AUTOSAR XML (schema 00051)
package /Components
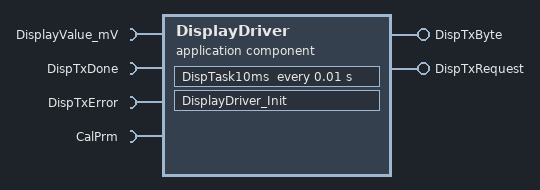
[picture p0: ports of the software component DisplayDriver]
  application sw component type DisplayDriver
    require port DisplayValue_mV: nonqueued-receiver-com-spec{data-element=DisplayValue_mV, init-value=0}, required-interface=DisplayValue_mV
    require port DispTxDone: nonqueued-receiver-com-spec{data-element=DispTxDone, init-value=0}, required-interface=DispTxDone
    require port DispTxError: nonqueued-receiver-com-spec{data-element=DispTxError, init-value=0}, required-interface=DispTxError
    provide port DispTxByte: nonqueued-sender-com-spec{data-element=DispTxByte, init-value=0}, provided-interface=DispTxByte
    provide port DispTxRequest: nonqueued-sender-com-spec{data-element=DispTxRequest, init-value=0}, provided-interface=DispTxRequest
    require port CalPrm: required-interface=CalPrm
      required-com-specs:
        init-value=CalPrm_DisplayRefresh_cycles:100, parameter=DisplayRefresh_cycles
        init-value=CalPrm_DisplayRetry_cycles:50, parameter=DisplayRetry_cycles
    behavior DisplayDriver_IB: handle-termination-and-restart=NO-SUPPORT
      timing event Event_DispTask10ms: start-on-event=DispTask10ms, period=0.01
      runnable DisplayDriver_Init
      runnable DispTask10ms
        data-receive-point-by-arguments:
          access IN_DispTxDone_DispTxDone: accessed-variable=DispTxDone.DispTxDone
          access IN_DispTxError_DispTxError: accessed-variable=DispTxError.DispTxError
          access IN_DisplayValue_mV_DisplayValue_mV: accessed-variable=DisplayValue_mV.DisplayValue_mV
        data-send-points:
          access OUT_DispTxByte_DispTxByte: accessed-variable=DispTxByte.DispTxByte
          access OUT_DispTxRequest_DispTxRequest: accessed-variable=DispTxRequest.DispTxRequest
        parameter access CALPRM_CalPrm_DisplayRefresh_cycles: accessed-parameter=CalPrm.DisplayRefresh_cycles
        parameter access CALPRM_CalPrm_DisplayRetry_cycles: accessed-parameter=CalPrm.DisplayRetry_cycles
